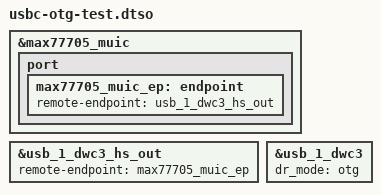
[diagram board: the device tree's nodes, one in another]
// SPDX-License-Identifier: MIT
/*
 * Bring-up overlay: enable OTG / dual-role on the dwc3 controller
 * and the MAX77705 MUIC/USBC extcon driver.
 *
 * Enables:
 *   - max77705-muic (USB cable detection via extcon)
 *   - dwc3 dr_mode = "otg" with extcon wiring
 *
 * The base DTS (sm8250-samsung-common.dtsi) already sets:
 *   - dr_mode = "peripheral"
 *   - usb-role-switch;
 *   - role-switch-default-mode = "peripheral";
 *
 * This overlay enables the MUIC and switches dr_mode to "otg" so the
 * extcon property on dwc3 can auto-switch role from cable detection.
 *
 * Usage:
 *   tools/r8q-boot pack --overlay usbc-otg-test
 *   tools/r8q-flash-recovery
 */
/dts-v1/;
/plugin/;

/* Enable the MAX77705 MUIC/USBC block and wire its role-switch graph to dwc3 */
&max77705_muic {
	status = "okay";

	port {
		max77705_muic_ep: endpoint {
			remote-endpoint = <&usb_1_dwc3_hs_out>;
		};
	};
};

&usb_1_dwc3_hs_out {
	remote-endpoint = <&max77705_muic_ep>;
};

/*
 * Enable OTG / dual-role on dwc3. Keep usb-role-switch (from base DTS) and do
 * NOT add extcon= here: extcon-max77705 is a module loaded after early boot,
 * and an extcon phandle on dwc3 would -EPROBE_DEFER USB gadget in initramfs.
 */
&usb_1_dwc3 {
	dr_mode = "otg";
};
